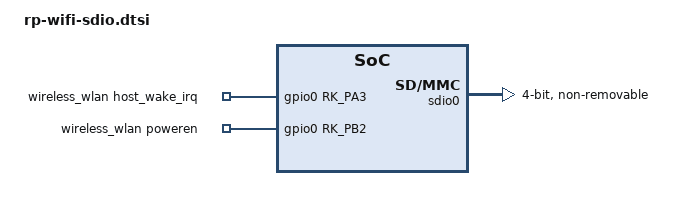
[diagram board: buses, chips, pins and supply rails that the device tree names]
/ {
    /*sdio_pwrseq: sdio-pwrseq {
        compatible = "mmc-pwrseq-simple";
        clocks = <&rk808 1>;
        clock-names = "ext_clock";
        pinctrl-names = "default";
        pinctrl-0 = <&wifi_enable_h>;

        /*
         * On the module itself this is one of these (depending
         * on the actual card populated):
         * - SDIO_RESET_L_WL_REG_ON
         * - PDN (power down when low)
         */
/*        reset-gpios = <&gpio0 RK_PB2 GPIO_ACTIVE_LOW>; /* GPIO0_B2 */
//    };

    wireless_wlan: wireless-wlan {
        compatible = "wlan-platdata";
        rockchip,grf = <&grf>;
        wifi_chip_type = "ap6210";
        sdio_vref = <1800>;
        pinctrl-names = "default";
                pinctrl-0 = <&wifi_host_wake_irq>, <&wifi_enable_h>;
        WIFI,host_wake_irq = <&gpio0 RK_PA3 GPIO_ACTIVE_HIGH>; /* GPIO0_a3 */
        WIFI,poweren_gpio = <&gpio0 RK_PB2 GPIO_ACTIVE_HIGH>;
        status = "okay";
    };
};


&sdio0 {
    max-frequency = <150000000>;
    no-sd;
    no-mmc;
    bus-width = <4>;
    disable-wp;
    cap-sd-highspeed;
    cap-sdio-irq;
    keep-power-in-suspend;
    //mmc-pwrseq = <&sdio_pwrseq>;
    non-removable;
    num-slots = <1>;
    pinctrl-names = "default";
    pinctrl-0 = <&sdio0_bus4 &sdio0_cmd &sdio0_clk>;
    sd-uhs-sdr104;
    status = "okay";
};

/*&uart0 {
    pinctrl-names = "default";
    pinctrl-0 = <&uart0_xfer &uart0_cts>;
    status = "okay";
};
*/
&pinctrl {
    /*sdio-pwrseq {
        wifi_enable_h: wifi-enable-h {
            rockchip,pins =
                <0 RK_PB2 RK_FUNC_GPIO &pcfg_pull_none>;
        };
*/
    wireless-wlan {
                wifi_host_wake_irq: wifi-host-wake-irq {
                        rockchip,pins = <0 RK_PA3 RK_FUNC_GPIO &pcfg_pull_down>;
                };
                wifi_enable_h: wifi-enable-h {
                        rockchip,pins = <0 RK_PB2 RK_FUNC_GPIO &pcfg_pull_up>;
                };

    };
};
